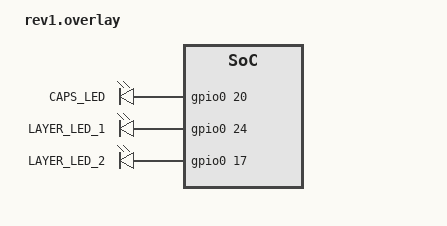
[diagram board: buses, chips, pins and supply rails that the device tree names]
/ {
    leds {
        compatible = "gpio-leds";

        led_caps: led_caps {
            gpios = <&gpio0 20 GPIO_ACTIVE_HIGH>;
            label = "CAPS_LED";
        };

        led_layer_1: led_layer_1 {
            gpios = <&gpio0 24 GPIO_ACTIVE_HIGH>;
            label = "LAYER_LED_1";
        };

        led_layer_2: led_layer_2 {
            gpios = <&gpio0 17 GPIO_ACTIVE_HIGH>;
            label = "LAYER_LED_2";
        };
    };
};
